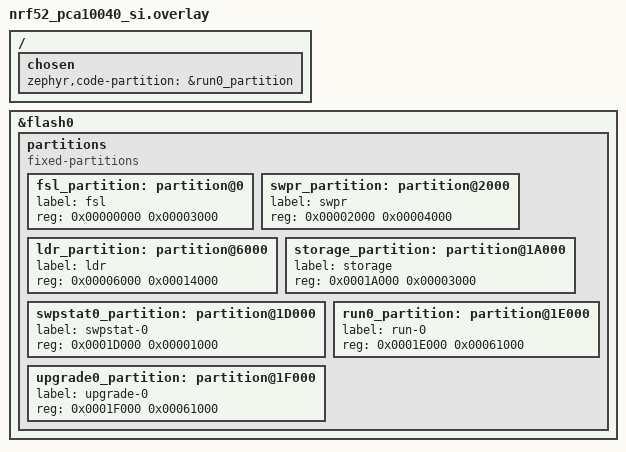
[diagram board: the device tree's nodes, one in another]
/*
 * Copyright (c) 2019 Laczen
 *
 * Overlay file for ZB-8 single image setup
 *
 * SPDX-License-Identifier: Apache-2.0
 */

/delete-node/ &boot_partition;
/delete-node/ &scratch_partition;
/delete-node/ &slot0_partition;
/delete-node/ &slot1_partition;
/delete-node/ &storage_partition;

/ {
	chosen {
		zephyr,code-partition = &run0_partition;
	};
};

&flash0 {
	/*
	 * For more information, see:
	 * http://docs.zephyrproject.org/latest/guides/dts/index.html#flash-partitions
	 */
	partitions {
		compatible = "fixed-partitions";
		#address-cells = <1>;
		#size-cells = <1>;

		fsl_partition: partition@0 {
			label = "fsl";
			reg = <0x00000000 0x00003000>;
		};
		swpr_partition: partition@2000 {
			label = "swpr";
			reg = <0x00002000 0x00004000>;
		};
		ldr_partition: partition@6000 {
			label = "ldr";
			reg = <0x00006000 0x00014000>;
		};
		storage_partition: partition@1A000 {
			label = "storage";
			reg = <0x0001A000 0x00003000>;
		};
		swpstat0_partition: partition@1D000 {
			label = "swpstat-0";
			reg = <0x0001D000 0x00001000>;
		};
		run0_partition: partition@1E000 {
			label = "run-0";
			reg = <0x0001E000 0x00061000>;
		};
		upgrade0_partition: partition@1F000 {
			label = "upgrade-0";
			reg = <0x0001F000 0x00061000>;
		};
	};
};
